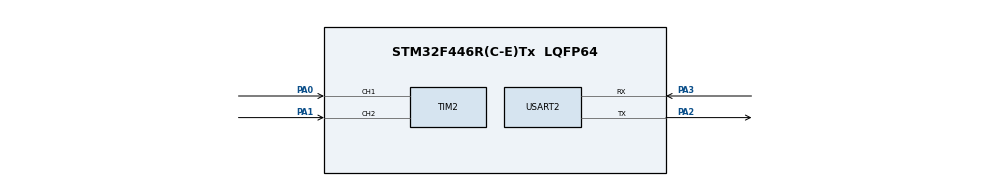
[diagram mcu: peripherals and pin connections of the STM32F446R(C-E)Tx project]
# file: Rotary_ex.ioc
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Dma.Request0=USART2_TX
Dma.USART2_TX.0.Direction=DMA_MEMORY_TO_PERIPH
Dma.USART2_TX.0.FIFOMode=DMA_FIFOMODE_DISABLE
Dma.USART2_TX.0.Instance=DMA1_Stream6
Dma.USART2_TX.0.MemDataAlignment=DMA_MDATAALIGN_BYTE
Dma.USART2_TX.0.MemInc=DMA_MINC_ENABLE
Dma.USART2_TX.0.Mode=DMA_NORMAL
Dma.USART2_TX.0.PeriphDataAlignment=DMA_PDATAALIGN_BYTE
Dma.USART2_TX.0.PeriphInc=DMA_PINC_DISABLE
Dma.USART2_TX.0.Priority=DMA_PRIORITY_LOW
Mcu.Family=STM32F4
Mcu.Name=STM32F446R(C-E)Tx
Mcu.Package=LQFP64
NVIC.DMA1_Stream6_IRQn=true\:0\:0\:false\:false\:true\:false\:true\:true
NVIC.PriorityGroup=NVIC_PRIORITYGROUP_4
NVIC.TIM2_IRQn=true\:0\:0\:false\:false\:true\:true\:true\:true
NVIC.USART2_IRQn=true\:0\:0\:false\:false\:true\:false\:true\:true
PA0-WKUP.Signal=S_TIM2_CH1_ETR
PA1.Signal=S_TIM2_CH2
PA13.Mode=Serial_Wire
PA13.Signal=SYS_JTMS-SWDIO
PA14.Mode=Serial_Wire
PA14.Signal=SYS_JTCK-SWCLK
PA2.Mode=Asynchronous
PA2.Signal=USART2_TX
PA3.Mode=Asynchronous
PA3.Signal=USART2_RX
ProjectManager.HeapSize=0x200
ProjectManager.StackSize=0x400
ProjectManager.TargetToolchain=CMake
RCC.CortexFreq_Value=16000000
RCC.USBFreq_Value=96000000
RCC.VCOOutputFreq_Value=192000000
SH.S_TIM2_CH1_ETR.0=TIM2_CH1,Encoder_Interface
SH.S_TIM2_CH2.0=TIM2_CH2,Encoder_Interface
USART2.VirtualMode=VM_ASYNC
board=custom

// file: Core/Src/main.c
/* USER CODE BEGIN Header */
/**
 ******************************************************************************
 * @file           : main.c
 * @brief          : Main program body
 ******************************************************************************
 * @attention
 *
 * Copyright (c) 2025 STMicroelectronics.
 * All rights reserved.
 *
 * This software is licensed under terms that can be found in the LICENSE file
 * in the root directory of this software component.
 * If no LICENSE file comes with this software, it is provided AS-IS.
 *
 ******************************************************************************
 */
/* USER CODE END Header */
#include "main.h"

/* USER CODE BEGIN Includes */
#include <stdio.h>
/* USER CODE END Includes */

TIM_HandleTypeDef htim2;

UART_HandleTypeDef huart2;
DMA_HandleTypeDef hdma_usart2_tx;

/* USER CODE BEGIN PV */
volatile uint32_t prev, curr;
uint8_t data[256];
uint16_t len;
/* USER CODE END PV */

void SystemClock_Config(void);
static void MX_GPIO_Init(void);
static void MX_DMA_Init(void);
static void MX_TIM2_Init(void);
static void MX_USART2_UART_Init(void);
/* USER CODE BEGIN PFP */
void HAL_TIM_IC_CaptureCallback(TIM_HandleTypeDef *htim)
{
  if (htim->Instance == TIM2)
  {
    curr = htim->Instance->CNT;
    if (prev != curr)
    {

      len = sprintf(data, "TIM2->CNT : %lu Direction : %s\r\n", curr, (prev < curr) ? "CW" : "CCW");
      prev = curr;
      if (HAL_UART_GetState(&huart2) == HAL_UART_STATE_READY)
      {
        HAL_UART_Transmit(&huart2, data, len, 0xff);
      }
    }
  }
}

/* USER CODE END PFP */

int main(void)
{

  /* MCU Configuration--------------------------------------------------------*/

  /* Reset of all peripherals, Initializes the Flash interface and the Systick. */
  HAL_Init();

  /* Configure the system clock */
  SystemClock_Config();

  /* Initialize all configured peripherals */
  MX_GPIO_Init();
  MX_DMA_Init();
  MX_TIM2_Init();
  MX_USART2_UART_Init();
  /* USER CODE BEGIN 2 */
  HAL_TIM_Encoder_Start_IT(&htim2, TIM_CHANNEL_ALL);

  /* USER CODE END 2 */

  /* Infinite loop */
  while (1)
  {

  }
}

void SystemClock_Config(void)
{
  RCC_OscInitTypeDef RCC_OscInitStruct = {0};
  RCC_ClkInitTypeDef RCC_ClkInitStruct = {0};

  /** Configure the main internal regulator output voltage
   */
  __HAL_RCC_PWR_CLK_ENABLE();
  __HAL_PWR_VOLTAGESCALING_CONFIG(PWR_REGULATOR_VOLTAGE_SCALE3);

  /** Initializes the RCC Oscillators according to the specified parameters
   * in the RCC_OscInitTypeDef structure.
   */
  RCC_OscInitStruct.OscillatorType = RCC_OSCILLATORTYPE_HSI;
  RCC_OscInitStruct.HSIState = RCC_HSI_ON;
  RCC_OscInitStruct.HSICalibrationValue = RCC_HSICALIBRATION_DEFAULT;
  RCC_OscInitStruct.PLL.PLLState = RCC_PLL_NONE;
  if (HAL_RCC_OscConfig(&RCC_OscInitStruct) != HAL_OK)
  {
    Error_Handler();
  }

  /** Initializes the CPU, AHB and APB buses clocks
   */
  RCC_ClkInitStruct.ClockType = RCC_CLOCKTYPE_HCLK | RCC_CLOCKTYPE_SYSCLK | RCC_CLOCKTYPE_PCLK1 | RCC_CLOCKTYPE_PCLK2;
  RCC_ClkInitStruct.SYSCLKSource = RCC_SYSCLKSOURCE_HSI;
  RCC_ClkInitStruct.AHBCLKDivider = RCC_SYSCLK_DIV1;
  RCC_ClkInitStruct.APB1CLKDivider = RCC_HCLK_DIV1;
  RCC_ClkInitStruct.APB2CLKDivider = RCC_HCLK_DIV1;

  if (HAL_RCC_ClockConfig(&RCC_ClkInitStruct, FLASH_LATENCY_0) != HAL_OK)
  {
    Error_Handler();
  }
}

static void MX_TIM2_Init(void)
{

  TIM_Encoder_InitTypeDef sConfig = {0};
  TIM_MasterConfigTypeDef sMasterConfig = {0};

  htim2.Instance = TIM2;
  htim2.Init.Prescaler = 0;
  htim2.Init.CounterMode = TIM_COUNTERMODE_UP;
  htim2.Init.Period = 4294967295;
  htim2.Init.ClockDivision = TIM_CLOCKDIVISION_DIV1;
  htim2.Init.AutoReloadPreload = TIM_AUTORELOAD_PRELOAD_DISABLE;
  sConfig.EncoderMode = TIM_ENCODERMODE_TI1;
  sConfig.IC1Polarity = TIM_ICPOLARITY_RISING;
  sConfig.IC1Selection = TIM_ICSELECTION_DIRECTTI;
  sConfig.IC1Prescaler = TIM_ICPSC_DIV1;
  sConfig.IC1Filter = 0;
  sConfig.IC2Polarity = TIM_ICPOLARITY_RISING;
  sConfig.IC2Selection = TIM_ICSELECTION_DIRECTTI;
  sConfig.IC2Prescaler = TIM_ICPSC_DIV1;
  sConfig.IC2Filter = 0;
  if (HAL_TIM_Encoder_Init(&htim2, &sConfig) != HAL_OK)
  {
    Error_Handler();
  }
  sMasterConfig.MasterOutputTrigger = TIM_TRGO_RESET;
  sMasterConfig.MasterSlaveMode = TIM_MASTERSLAVEMODE_DISABLE;
  if (HAL_TIMEx_MasterConfigSynchronization(&htim2, &sMasterConfig) != HAL_OK)
  {
    Error_Handler();
  }
}

static void MX_USART2_UART_Init(void)
{

  huart2.Instance = USART2;
  huart2.Init.BaudRate = 115200;
  huart2.Init.WordLength = UART_WORDLENGTH_8B;
  huart2.Init.StopBits = UART_STOPBITS_1;
  huart2.Init.Parity = UART_PARITY_NONE;
  huart2.Init.Mode = UART_MODE_TX_RX;
  huart2.Init.HwFlowCtl = UART_HWCONTROL_NONE;
  huart2.Init.OverSampling = UART_OVERSAMPLING_16;
  if (HAL_UART_Init(&huart2) != HAL_OK)
  {
    Error_Handler();
  }
}

static void MX_DMA_Init(void)
{

  /* DMA controller clock enable */
  __HAL_RCC_DMA1_CLK_ENABLE();

  /* DMA interrupt init */
  /* DMA1_Stream6_IRQn interrupt configuration */
  HAL_NVIC_SetPriority(DMA1_Stream6_IRQn, 0, 0);
  HAL_NVIC_EnableIRQ(DMA1_Stream6_IRQn);
}

static void MX_GPIO_Init(void)
{

  /* GPIO Ports Clock Enable */
  __HAL_RCC_GPIOA_CLK_ENABLE();

}

void Error_Handler(void)
{
  __disable_irq();
  while (1)
  {
  }
}
